# ESP32-P4 register map
Vendor: ESPRESSIF SYSTEMS (SHANGHAI) CO., LTD.; Series: ESP32 P-Series; File version: 3
CPU: RV32IMAFC r0p0, little endian, no MPU, FPU, 0 interrupt priority bits
Address unit: 32 bits
Registers are 32-bit, read-write, reset 0x0 unless marked. A register's access mark holds for its fields unless they carry their own. Offsets are from the block's base; [hi:lo] are bit positions; {n}, {i} and the like mark numbered series; 'fields as' and 'values as' point back to an identical list.

## LP_TOUCH — LP_TOUCH Peripheral
Base 0x50128000
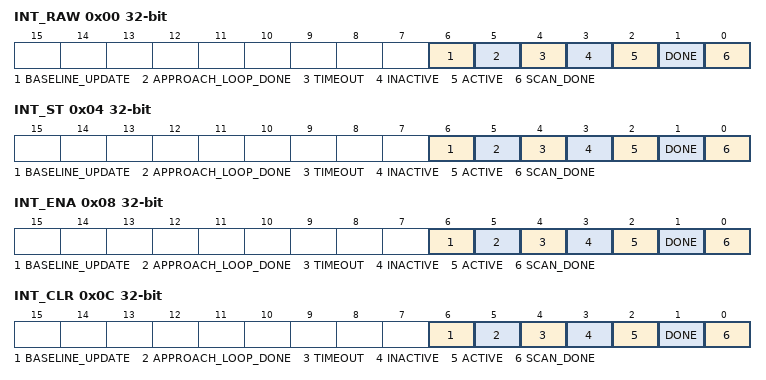
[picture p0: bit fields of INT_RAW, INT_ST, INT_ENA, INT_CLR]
0x00 INT_RAW — need_des
  [6] BASELINE_UPDATE — need_des
  [5] APPROACH_LOOP_DONE — need_des
  [4] TIMEOUT — need_des
  [3] INACTIVE — need_des
  [2] ACTIVE — need_des
  [1] DONE — need_des
  [0] SCAN_DONE — need_des
0x04 INT_ST ro — need_des
  fields as INT_RAW
0x08 INT_ENA — need_des
  fields as INT_RAW
0x0C INT_CLR wo — need_des
  [6] BASELINE_UPDATE write-1-clears — need_des
  [5] APPROACH_LOOP_DONE write-1-clears — need_des
  [4] TIMEOUT write-1-clears — need_des
  [3] INACTIVE write-1-clears — need_des
  [2] ACTIVE write-1-clears — need_des
  [1] DONE write-1-clears — need_des
  [0] SCAN_DONE write-1-clears — need_des
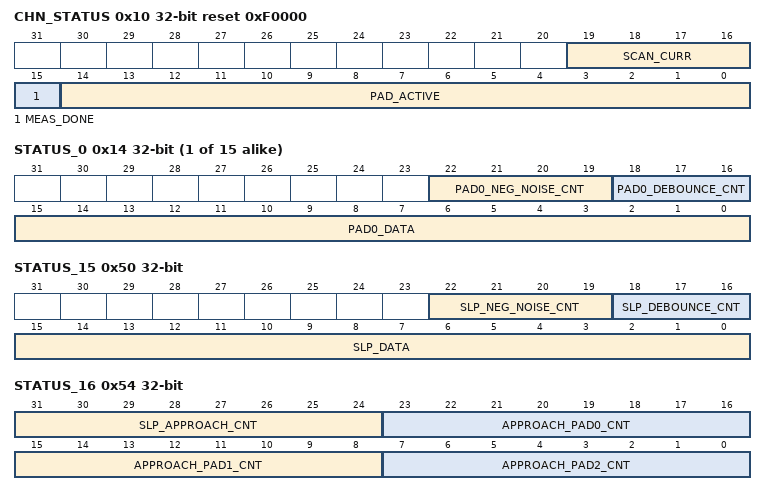
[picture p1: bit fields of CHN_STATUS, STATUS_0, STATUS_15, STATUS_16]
0x10 CHN_STATUS ro reset 0xF0000 — need_des
  [19:16] SCAN_CURR — need_des
  [15] MEAS_DONE — need_des
  [14:0] PAD_ACTIVE — need_des
{0x14+4i} STATUS_{i} ro (i=0..14) — need_des
  [22:19] PAD{i}_NEG_NOISE_CNT — need_des
  [18:16] PAD{i}_DEBOUNCE_CNT — need_des
  [15:0] PAD{i}_DATA — need_des
0x50 STATUS_15 ro — need_des
  [22:19] SLP_NEG_NOISE_CNT — need_des
  [18:16] SLP_DEBOUNCE_CNT — need_des
  [15:0] SLP_DATA — need_des
0x54 STATUS_16 ro — need_des
  [31:24] SLP_APPROACH_CNT — need_des
  [23:16] APPROACH_PAD0_CNT — need_des
  [15:8] APPROACH_PAD1_CNT — need_des
  [7:0] APPROACH_PAD2_CNT — need_des
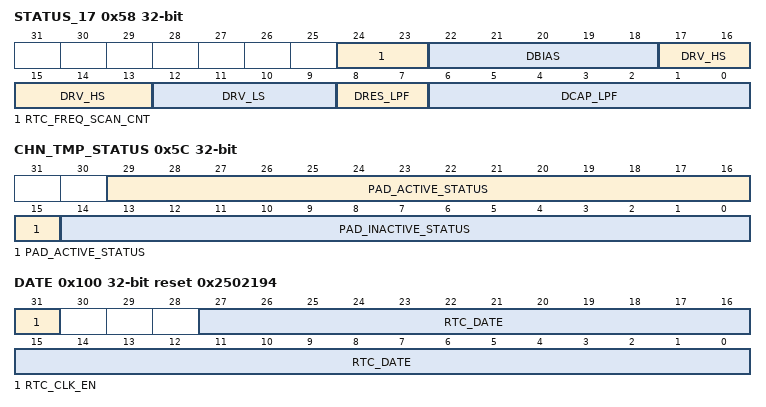
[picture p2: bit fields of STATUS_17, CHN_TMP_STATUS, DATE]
0x58 STATUS_17 ro — need_des
  [24:23] RTC_FREQ_SCAN_CNT — need_des
  [22:18] DBIAS — need_des
  [17:13] DRV_HS — need_des
  [12:9] DRV_LS — need_des
  [8:7] DRES_LPF — need_des
  [6:0] DCAP_LPF — Reserved
0x5C CHN_TMP_STATUS ro — need_des
  [29:15] PAD_ACTIVE_STATUS — need_des
  [14:0] PAD_INACTIVE_STATUS — need_des
0x100 DATE reset 0x2502194 — need_des
  [31] RTC_CLK_EN — need_des
  [27:0] RTC_DATE — need_des

## LP_WDT — Low-power Watchdog Timer
Base 0x50116000
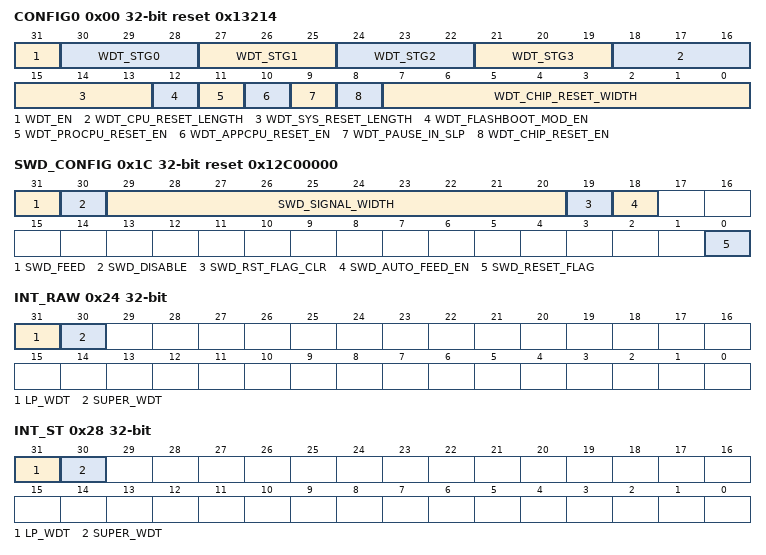
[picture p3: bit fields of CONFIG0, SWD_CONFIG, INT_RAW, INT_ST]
0x00 CONFIG0 reset 0x13214 — need_des
  [31] WDT_EN — need_des
  [30-3n:28-3n] WDT_STG{n} (n=0..3) — need_des
  [18:16] WDT_CPU_RESET_LENGTH — need_des
  [15:13] WDT_SYS_RESET_LENGTH — need_des
  [12] WDT_FLASHBOOT_MOD_EN — need_des
  [11] WDT_PROCPU_RESET_EN — need_des
  [10] WDT_APPCPU_RESET_EN — need_des
  [9] WDT_PAUSE_IN_SLP — need_des
  [8] WDT_CHIP_RESET_EN — need_des
  [7:0] WDT_CHIP_RESET_WIDTH — need_des
{0x0+4i} CONFIG{i} (i=1..4) reset 0x30D40 — WDT configuration register
  [31:0] HOLD — need_des
0x14 FEED wo — need_des
  [31] FEED
0x18 WPROTECT — need_des
  [31:0] WDT_WKEY
0x1C SWD_CONFIG access per field reset 0x12C00000 — need_des
  [31] SWD_FEED wo — need_des
  [30] SWD_DISABLE rw — need_des
  [29:20] SWD_SIGNAL_WIDTH rw — need_des
  [19] SWD_RST_FLAG_CLR wo — need_des
  [18] SWD_AUTO_FEED_EN rw — need_des
  [0] SWD_RESET_FLAG ro — need_des
0x20 SWD_WPROTECT — need_des
  [31:0] SWD_WKEY
0x24 INT_RAW — need_des
  [31] LP_WDT — need_des
  [30] SUPER_WDT — need_des
0x28 INT_ST ro — need_des
  [31] LP_WDT — need_des
  [30] SUPER_WDT — need_des
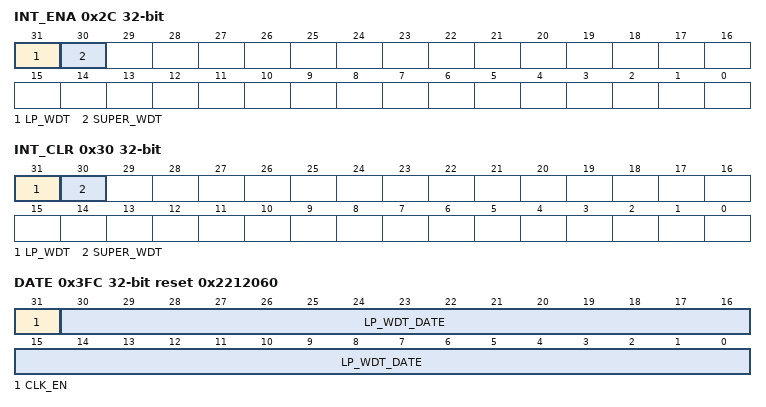
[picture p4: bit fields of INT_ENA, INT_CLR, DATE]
0x2C INT_ENA — need_des
  [31] LP_WDT — need_des
  [30] SUPER_WDT — need_des
0x30 INT_CLR wo — need_des
  [31] LP_WDT write-1-clears — need_des
  [30] SUPER_WDT write-1-clears — need_des
0x3FC DATE reset 0x2212060 — need_des
  [31] CLK_EN — need_des
  [30:0] LP_WDT_DATE — need_des

## SHA — SHA (Secure Hash Algorithm) Accelerator
Base 0x50091000
0x00 MODE — Configures SHA algorithm
  [2:0] MODE — Configures the SHA algorithm. \\ 0: SHA-1\\ 1: SHA-224\\ 2: SHA-256\\ 3: SHA2-384\\ 4: SHA2-512\\ 5: SHA2-512/224\\ 6: SHA2-512/256\\ 7: SHA2-512/t\\
0x04 T_STRING — SHA 512/t configuration register 0.
  [31:0] T_STRING — Sha t_string (used if and only if mode == SHA_512/t).
0x08 T_LENGTH — SHA 512/t configuration register 1.
  [6:0] T_LENGTH — Sha t_length (used if and only if mode == SHA_512/t).
0x0C DMA_BLOCK_NUM — Block number register (only effective for DMA-SHA)
  [15:0] DMA_BLOCK_NUM — Configures the DMA-SHA block number.
0x10 START wo — Starts the SHA accelerator for Typical SHA operation
  [0] START — Write 1 to start Typical SHA calculation.
0x14 CONTINUE wo — Continues SHA operation (only effective in Typical SHA mode)
  [0] CONTINUE — Write 1 to continue Typical SHA calculation.
0x18 BUSY ro — Represents if SHA Accelerator is busy or not
  [0] STATE — Represents the states of SHA accelerator. \\ 0: idle\\ 1: busy\\
0x1C DMA_START wo — Starts the SHA accelerator for DMA-SHA operation
  [0] DMA_START — Write 1 to start DMA-SHA calculation.
0x20 DMA_CONTINUE wo — Continues SHA operation (only effective in DMA-SHA mode)
  [0] DMA_CONTINUE — Write 1 to continue DMA-SHA calculation.
0x24 CLEAR_IRQ wo — DMA-SHA interrupt clear register
  [0] CLEAR_INTERRUPT — Write 1 to clear DMA-SHA interrupt.
0x28 IRQ_ENA — DMA-SHA interrupt enable register
  [0] INTERRUPT_ENA — Write 1 to enable DMA-SHA interrupt.
0x2C DATE reset 0x20240823 — Version control register
  [29:0] DATE — Version control register.
0x30 DMA_RX_RESET wo — DMA RX FIFO Reset Signal
  [0] DMA_RX_RESET — Write 1 to reset DMA RX FIFO
{0x40+4i} H_MEM[{i}] (i=0..15) access not given — Sha H memory which contains intermediate hash or finial hash.
{0x80+4i} M_MEM[{i}] (i=0..31) access not given — Sha M memory which contains message.
